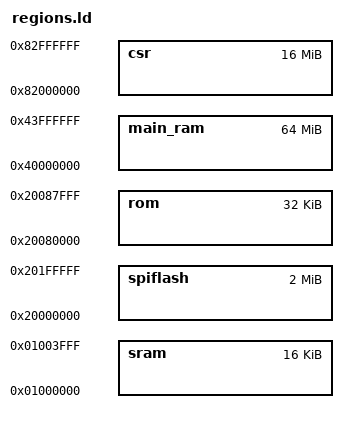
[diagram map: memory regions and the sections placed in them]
MEMORY {
	sram : ORIGIN = 0x01000000, LENGTH = 0x00004000
	csr : ORIGIN = 0x82000000, LENGTH = 0x01000000
	spiflash : ORIGIN = 0x20000000, LENGTH = 0x00200000
	rom : ORIGIN = 0x20080000, LENGTH = 0x00008000
	main_ram : ORIGIN = 0x40000000, LENGTH = 0x04000000
}
